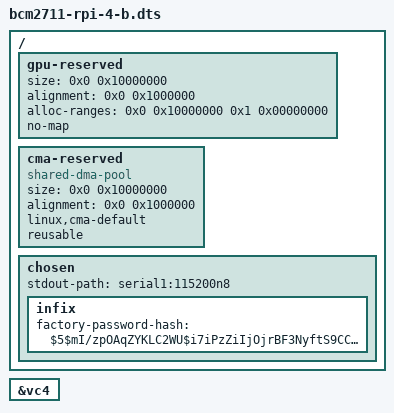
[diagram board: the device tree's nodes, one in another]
#include <arm64/broadcom/bcm2711-rpi-4-b.dts>

/ {
	/* Dynamic GPU reservation */
	gpu-reserved {
		size = <0x0 0x10000000>; /* 256MB */
		alignment = <0x0 0x1000000>; /* 16MB aligned */
		alloc-ranges = <0x0 0x10000000 0x1 0x00000000>; /* Allow anywhere in RAM */
		no-map;
	};

	/* CMA pool */
	cma-reserved {
		compatible = "shared-dma-pool";
		size = <0x0 0x10000000>; /* 256MB */
		alignment = <0x0 0x1000000>; /* 16MB aligned */
		linux,cma-default;
		reusable;
	};

	chosen {
		/* 8250 auxiliary UART instead of pl011 */
		stdout-path = "serial1:115200n8";

		infix {
			/* Default admin user password: 'admin' */
			factory-password-hash = "$5$mI/zpOAqZYKLC2WU$i7iPzZiIjOjrBF3NyftS9CCq8dfYwHwrmUK097Jca9A";
		};
	};
};


&vc4 {
	status = "okay";
};
